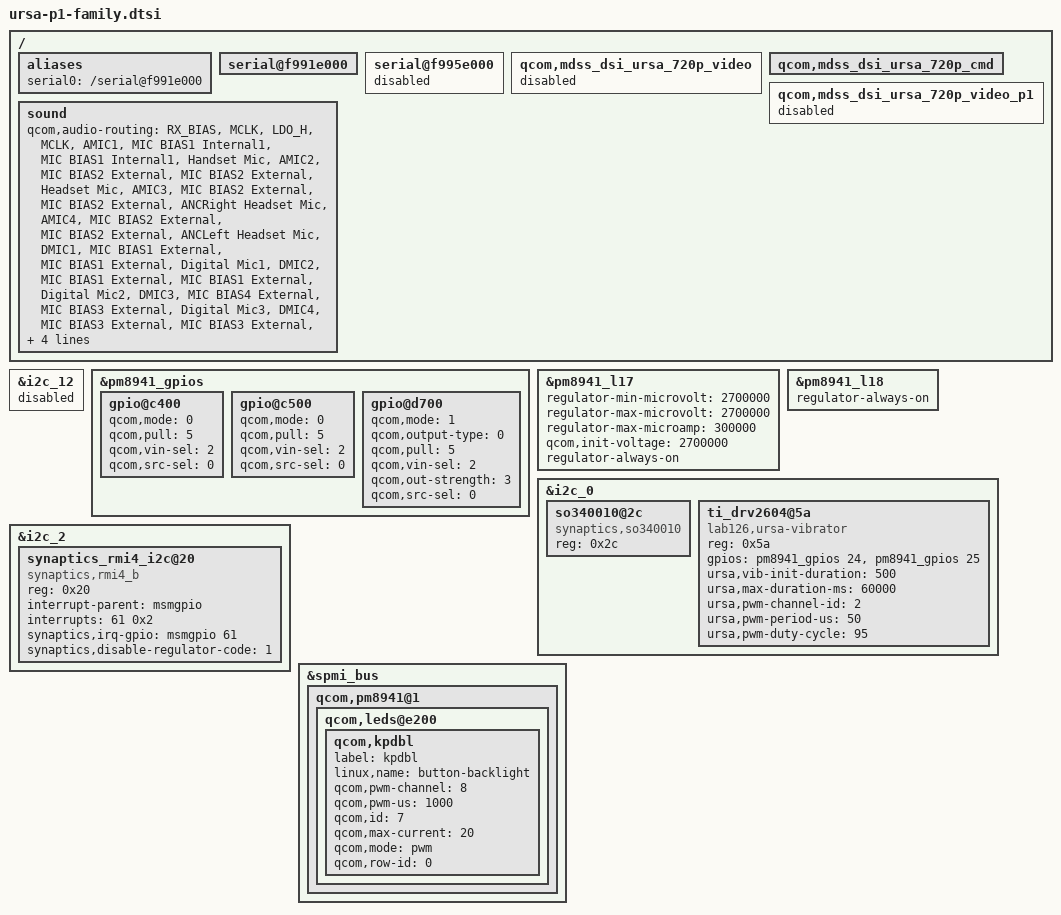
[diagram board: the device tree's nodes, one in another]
/* Copyright (c) 2013, The Linux Foundation. All rights reserved.
 *
 * This program is free software; you can redistribute it and/or modify
 * it under the terms of the GNU General Public License version 2 and
 * only version 2 as published by the Free Software Foundation.
 *
 * This program is distributed in the hope that it will be useful,
 * but WITHOUT ANY WARRANTY; without even the implied warranty of
 * MERCHANTABILITY or FITNESS FOR A PARTICULAR PURPOSE.  See the
 * GNU General Public License for more details.
 */

 /* This device-tree include has properties common to Pre-P1, P1 and
  * P0.5 devices. Properties specific to a particular board go in board
  * specific .dts.
  */

/ {
	aliases {
		serial0 = "/serial@f991e000";
	};

	serial@f991e000 {
		status = "ok";
	};

	serial@f995e000 {
		status = "disabled";
	};

	qcom,mdss_dsi_ursa_720p_video {
		status = "disabled";
	};

	qcom,mdss_dsi_ursa_720p_cmd {
		status = "ok";
	};

	qcom,mdss_dsi_ursa_720p_video_p1 {
		status = "disabled";
	};

	sound {
		qcom,audio-routing =
			"RX_BIAS", "MCLK",
			"LDO_H", "MCLK",
			"AMIC1", "MIC BIAS1 Internal1",
			"MIC BIAS1 Internal1", "Handset Mic",
			"AMIC2", "MIC BIAS2 External",
			"MIC BIAS2 External", "Headset Mic",
			"AMIC3", "MIC BIAS2 External",
			"MIC BIAS2 External", "ANCRight Headset Mic",
			"AMIC4", "MIC BIAS2 External",
			"MIC BIAS2 External", "ANCLeft Headset Mic",
			"DMIC1", "MIC BIAS1 External",
			"MIC BIAS1 External", "Digital Mic1",
			"DMIC2", "MIC BIAS1 External",
			"MIC BIAS1 External", "Digital Mic2",
			"DMIC3", "MIC BIAS4 External",
			"MIC BIAS3 External", "Digital Mic3",
			"DMIC4", "MIC BIAS3 External",
			"MIC BIAS3 External", "Digital Mic4",
			"DMIC5", "MIC BIAS4 External",
			"MIC BIAS4 External", "Digital Mic5",
			"DMIC6", "MIC BIAS4 External",
			"MIC BIAS4 External", "Digital Mic6";
	};
};

/* I2C overrides */
&i2c_12 {
	status = "disabled";
};

&pm8941_gpios {
	gpio@c400 { /* GPIO 5 HOME_BUTTON_INT_N */
		qcom,mode = <0>;
		qcom,pull = <5>;
		qcom,vin-sel = <2>;
		qcom,src-sel = <0>;
	};

	gpio@c500 { /* GPIO 6 HOME_BUTTON_OUT */
		qcom,mode = <0>;
		qcom,pull = <5>;
		qcom,vin-sel = <2>;
		qcom,src-sel = <0>;
	};

	gpio@d700 { /* GPIO 24 VIB_EN */
		qcom,mode = <1>;
		qcom,output-type = <0>;
		qcom,pull = <5>;
		qcom,vin-sel = <2>;
		qcom,out-strength = <3>;
		qcom,src-sel = <0>;
	};
};

&pm8941_l17 {
	regulator-min-microvolt = <2700000>;
	regulator-max-microvolt = <2700000>;
	regulator-max-microamp = <300000>;
	qcom,init-voltage = <2700000>;

	/* workaround for home button i2c 0 issue */
	regulator-always-on;
};

&pm8941_l18 {
	/* workaround for atiny i2c 0 issue */
	regulator-always-on;
};

&i2c_0 {
	so340010@2c {   /* Capacitive home button */
		compatible = "synaptics,so340010";
		reg = <0x2c>;
	};

	ti_drv2604@5a { /* Ursa vibrator */
		compatible = "lab126,ursa-vibrator";
		reg = <0x5a>; /* i2c address */
		gpios = <&pm8941_gpios 24 0>, /* vib_enable pin is PMIC gpio 24 */
			<&pm8941_gpios 25 0>; /* IN/TRIG pin (vib_control) is PMIC gpio 25 */
		ursa,vib-init-duration = <500>; /* initial vibration for 0.5 sec */
		ursa,max-duration-ms = <60000>; /* maxmimum allowed vibration duration is 60sec */
		ursa,pwm-channel-id = <2>; /* use pwm channel 3 */
		ursa,pwm-period-us = <50>; /* 20Khz */
		ursa,pwm-duty-cycle = <95>; /* 95% duty cycle */
	};
};

&i2c_2 {
	synaptics_rmi4_i2c@20 {
		compatible = "synaptics,rmi4_b";
		reg = <0x20>;
		//Note: These IRQ flags are overridden by the driver code
		interrupt-parent = <&msmgpio>;
		interrupts = <61 0x2>;
		synaptics,irq-gpio = <&msmgpio 61 0x00>;
		synaptics,disable-regulator-code = <1>;
	};
};

&spmi_bus {
	qcom,pm8941@1 {
		qcom,leds@e200 {
			status = "okay";
			qcom,kpdbl {
				label = "kpdbl";
				linux,name = "button-backlight";
				qcom,pwm-channel = <8>;
				qcom,pwm-us = <1000>;
				qcom,id = <7>;
				qcom,max-current = <20>;
				qcom,mode = "pwm";
				qcom,row-id = <0>;
			};
		};
	};
};
